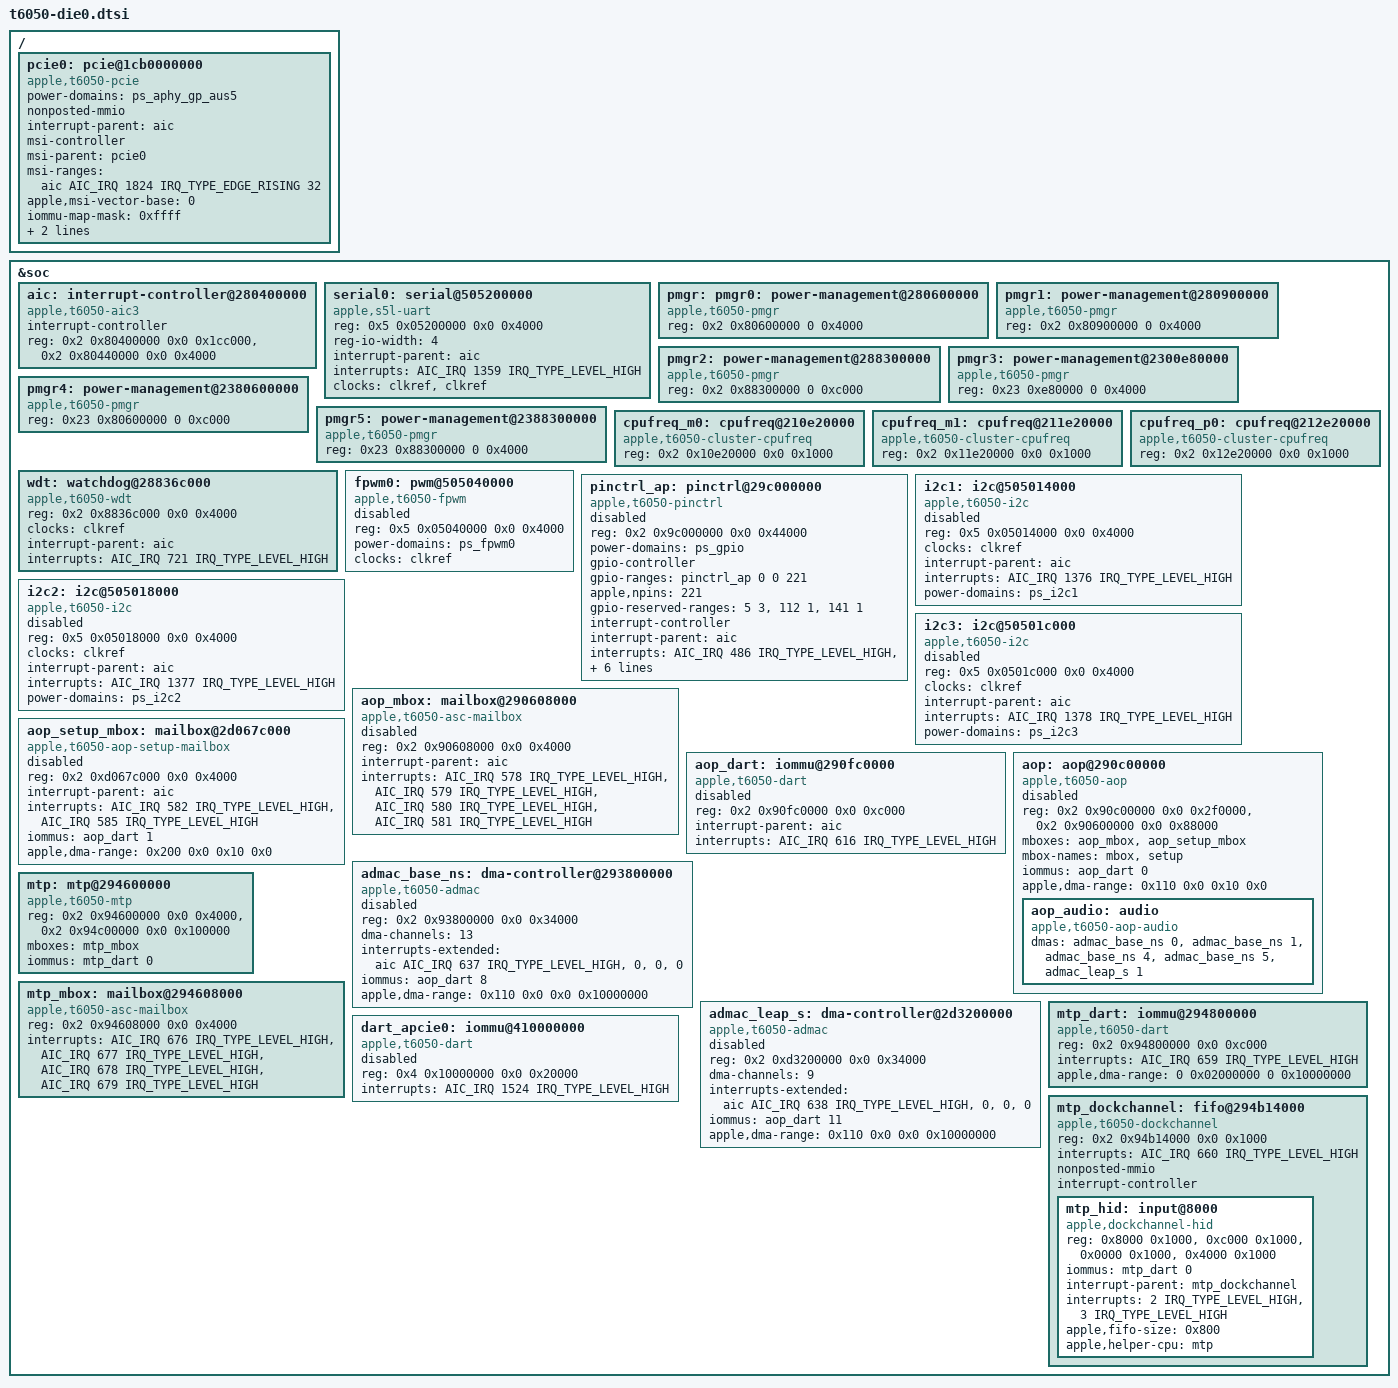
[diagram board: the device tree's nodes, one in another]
// SPDX-License-Identifier: GPL-2.0+ OR MIT
/*
 * Devices on the Apple T6050 "M5 Max" SoC (single die)
 *
 * Register windows from the live J714c device tree (dumps/j714c.adt).
 * The six pmgr register blocks are declared here; their power domains
 * live in t6050-pmgr.dtsi.
 *
 * Copyright The Asahi Linux Contributors
 */

&soc {
	aic: interrupt-controller@280400000 {
		compatible = "apple,t6050-aic3", "apple,t8142-aic3", "apple,t8122-aic3";
		#interrupt-cells = <3>;
		interrupt-controller;

		reg = <0x2 0x80400000 0x0 0x1cc000>,
		      <0x2 0x80440000 0x0 0x4000>;
		reg-names = "core", "event";
	};

	serial0: serial@505200000 {
		compatible = "apple,s5l-uart";
		reg = <0x5 0x05200000 0x0 0x4000>;
		reg-io-width = <4>;
		interrupt-parent = <&aic>;
		interrupts = <AIC_IRQ 1359 IRQ_TYPE_LEVEL_HIGH>;
		clocks = <&clkref>, <&clkref>;
		clock-names = "uart", "clk_uart_baud0";
	};

	pmgr: pmgr0: power-management@280600000 {
		compatible = "apple,t6050-pmgr", "apple,t8103-pmgr", "syscon", "simple-mfd";
		reg = <0x2 0x80600000 0 0x4000>;
		#address-cells = <1>;
		#size-cells = <1>;
	};

	pmgr1: power-management@280900000 {
		compatible = "apple,t6050-pmgr", "apple,t8103-pmgr", "syscon", "simple-mfd";
		reg = <0x2 0x80900000 0 0x4000>;
		#address-cells = <1>;
		#size-cells = <1>;
	};

	pmgr2: power-management@288300000 {
		compatible = "apple,t6050-pmgr", "apple,t8103-pmgr", "syscon", "simple-mfd";
		reg = <0x2 0x88300000 0 0xc000>;
		#address-cells = <1>;
		#size-cells = <1>;
	};

	pmgr3: power-management@2300e80000 {
		compatible = "apple,t6050-pmgr", "apple,t8103-pmgr", "syscon", "simple-mfd";
		reg = <0x23 0xe80000 0 0x4000>;
		#address-cells = <1>;
		#size-cells = <1>;
	};

	pmgr4: power-management@2380600000 {
		compatible = "apple,t6050-pmgr", "apple,t8103-pmgr", "syscon", "simple-mfd";
		reg = <0x23 0x80600000 0 0xc000>;
		#address-cells = <1>;
		#size-cells = <1>;
	};

	pmgr5: power-management@2388300000 {
		compatible = "apple,t6050-pmgr", "apple,t8103-pmgr", "syscon", "simple-mfd";
		reg = <0x23 0x88300000 0 0x4000>;
		#address-cells = <1>;
		#size-cells = <1>;
	};

	cpufreq_m0: cpufreq@210e20000 {
		compatible = "apple,t6050-cluster-cpufreq", "apple,cluster-cpufreq";
		reg = <0x2 0x10e20000 0x0 0x1000>;
		#performance-domain-cells = <0>;
	};

	cpufreq_m1: cpufreq@211e20000 {
		compatible = "apple,t6050-cluster-cpufreq", "apple,cluster-cpufreq";
		reg = <0x2 0x11e20000 0x0 0x1000>;
		#performance-domain-cells = <0>;
	};

	cpufreq_p0: cpufreq@212e20000 {
		compatible = "apple,t6050-cluster-cpufreq", "apple,cluster-cpufreq";
		reg = <0x2 0x12e20000 0x0 0x1000>;
		#performance-domain-cells = <0>;
	};

	wdt: watchdog@28836c000 {
		compatible = "apple,t6050-wdt", "apple,t8103-wdt";
		reg = <0x2 0x8836c000 0x0 0x4000>;
		clocks = <&clkref>;
		interrupt-parent = <&aic>;
		interrupts = <AIC_IRQ 721 IRQ_TYPE_LEVEL_HIGH>;
	};

	fpwm0: pwm@505040000 {
		compatible = "apple,t6050-fpwm", "apple,s5l-fpwm";
		reg = <0x5 0x05040000 0x0 0x4000>;
		power-domains = <&ps_fpwm0>;
		clocks = <&clkref>;
		#pwm-cells = <2>;
		status = "disabled";
	};

	/*
	 * AP GPIO block. ADT /arm-io/gpio0: 0x9c000000 + 0x44000, 221 pins,
	 * seven AIC interrupts, no-restore-gpio-pins 5 6 7 112 141. The t8140
	 * driver variant: slots in the block fault when read, so the regmap is
	 * not cache-initialised and stays inside the valid pins minus the
	 * reserved ranges (the firmware's no-restore pins, as t8140.dtsi).
	 * Enabled by the board DT together with its first users, the audio
	 * codec reset, shutdown and interrupt lines.
	 */
	pinctrl_ap: pinctrl@29c000000 {
		compatible = "apple,t6050-pinctrl", "apple,t8140-pinctrl";
		reg = <0x2 0x9c000000 0x0 0x44000>;
		power-domains = <&ps_gpio>;

		gpio-controller;
		#gpio-cells = <2>;
		gpio-ranges = <&pinctrl_ap 0 0 221>;
		apple,npins = <221>;
		gpio-reserved-ranges = <5 3>, <112 1>, <141 1>;

		interrupt-controller;
		#interrupt-cells = <2>;
		interrupt-parent = <&aic>;
		interrupts = <AIC_IRQ 486 IRQ_TYPE_LEVEL_HIGH>,
			     <AIC_IRQ 487 IRQ_TYPE_LEVEL_HIGH>,
			     <AIC_IRQ 488 IRQ_TYPE_LEVEL_HIGH>,
			     <AIC_IRQ 489 IRQ_TYPE_LEVEL_HIGH>,
			     <AIC_IRQ 490 IRQ_TYPE_LEVEL_HIGH>,
			     <AIC_IRQ 491 IRQ_TYPE_LEVEL_HIGH>,
			     <AIC_IRQ 492 IRQ_TYPE_LEVEL_HIGH>;
		status = "disabled";
	};

	/*
	 * I2C controllers. ADT /arm-io/i2c1..3: 0x305014000, 0x305018000,
	 * 0x30501c000 (+ 0x4000 each), AIC interrupts 1376-1378, pmgr I2C1-3.
	 * SCL/SDA are AP pins 60/61, 62/63 and 64/65; iBoot leaves them muxed
	 * (it drives the speaker amps for the boot chime), so no pin groups are
	 * set here. i2c1 and i2c3 carry the speaker amps, i2c2 the jack codec.
	 */
	i2c1: i2c@505014000 {
		compatible = "apple,t6050-i2c", "apple,t8103-i2c";
		reg = <0x5 0x05014000 0x0 0x4000>;
		clocks = <&clkref>;
		interrupt-parent = <&aic>;
		interrupts = <AIC_IRQ 1376 IRQ_TYPE_LEVEL_HIGH>;
		#address-cells = <1>;
		#size-cells = <0>;
		power-domains = <&ps_i2c1>;
		status = "disabled";
	};

	i2c2: i2c@505018000 {
		compatible = "apple,t6050-i2c", "apple,t8103-i2c";
		reg = <0x5 0x05018000 0x0 0x4000>;
		clocks = <&clkref>;
		interrupt-parent = <&aic>;
		interrupts = <AIC_IRQ 1377 IRQ_TYPE_LEVEL_HIGH>;
		#address-cells = <1>;
		#size-cells = <0>;
		power-domains = <&ps_i2c2>;
		status = "disabled";
	};

	i2c3: i2c@50501c000 {
		compatible = "apple,t6050-i2c", "apple,t8103-i2c";
		reg = <0x5 0x0501c000 0x0 0x4000>;
		clocks = <&clkref>;
		interrupt-parent = <&aic>;
		interrupts = <AIC_IRQ 1378 IRQ_TYPE_LEVEL_HIGH>;
		#address-cells = <1>;
		#size-cells = <0>;
		power-domains = <&ps_i2c3>;
		status = "disabled";
	};

	/*
	 * AOP (always-on processor) and the audio DMA it owns. ADT /arm-io/aop
	 * (iop,ascwrap-v6, pre-loaded firmware mac17jaop): asc 0x90600000+0x88000,
	 * mmio 0x90c00000+0x2f0000, mailbox AIC 578-581 (ADT order [579 578 581
	 * 580] = send-not-empty, send-empty, recv-not-empty, recv-empty, as mtp);
	 * no AP power or clock gates. /arm-io/aop-exclave-mailbox
	 * (iop,secure-rtbuddy-proxy, T8140's "setup port"): 0x2d067c000+0x4000,
	 * ADT interrupts [585 582], dart-aop mapper 1; reading it hangs the AP,
	 * and the firmware boots without it, so it is not described. /arm-io/dart-aop:
	 * 0x90fc0000+0xc000, AIC 616, mappers aop 0, exclave-aop 1,
	 * admac-base-ns 8, admac-leap-ns 10, admac-leap-s 11.
	 * /arm-io/admac-base-ns (admac-evolution,t6050): 0x93800000+0x34000,
	 * AIC 637, 13 tx + 13 rx channels. DMA windows as t8140.dtsi: the ADT
	 * has the same vm-base-0 (0x10040000000) and vm-base-1 (0x20000000000).
	 */
	aop_mbox: mailbox@290608000 {
		compatible = "apple,t6050-asc-mailbox", "apple,asc-mailbox-v4";
		reg = <0x2 0x90608000 0x0 0x4000>;
		interrupt-parent = <&aic>;
		interrupts = <AIC_IRQ 578 IRQ_TYPE_LEVEL_HIGH>,
			     <AIC_IRQ 579 IRQ_TYPE_LEVEL_HIGH>,
			     <AIC_IRQ 580 IRQ_TYPE_LEVEL_HIGH>,
			     <AIC_IRQ 581 IRQ_TYPE_LEVEL_HIGH>;
		interrupt-names = "send-empty", "send-not-empty",
				  "recv-empty", "recv-not-empty";
		#mbox-cells = <0>;
		status = "disabled";
	};

	/*
	 * The AOP's "setup port": ADT /arm-io/aop-exclave-mailbox
	 * (iop,secure-rtbuddy-proxy), the ASC's second mailbox 1 GiB above
	 * it as on T8140, interrupts [585, 582], messages through dart-aop
	 * stream 1 (mapper-exclave-aop, vm-base-1 0x20000000000). The
	 * firmware's TRUSTED compartment serves three endpoints on it (0x20,
	 * 0x23, 0x32) and may only use DRAM in that stream-1 window; its AFK
	 * endpoints on the main mailbox answer only after this handshake.
	 */
	aop_setup_mbox: mailbox@2d067c000 {
		compatible = "apple,t6050-aop-setup-mailbox", "apple,t8140-aop-setup-mailbox";
		reg = <0x2 0xd067c000 0x0 0x4000>;
		interrupt-parent = <&aic>;
		interrupts = <AIC_IRQ 582 IRQ_TYPE_LEVEL_HIGH>,
			     <AIC_IRQ 585 IRQ_TYPE_LEVEL_HIGH>;
		interrupt-names = "send-empty", "recv-not-empty";
		iommus = <&aop_dart 1>;
		apple,dma-range = <0x200 0x0 0x10 0x0>;
		#mbox-cells = <0>;
		status = "disabled";
	};

	aop_dart: iommu@290fc0000 {
		/*
		 * Locked by the loader with inherited roots, like mtp_dart: the
		 * t8142 compatible turns on apple-dart's retained-root path
		 * (fw_mirror), which the plain t8110 fallback leaves off.
		 */
		compatible = "apple,t6050-dart", "apple,t8142-dart", "apple,t8110-dart";
		reg = <0x2 0x90fc0000 0x0 0xc000>;
		#iommu-cells = <1>;
		interrupt-parent = <&aic>;
		interrupts = <AIC_IRQ 616 IRQ_TYPE_LEVEL_HIGH>;
		status = "disabled";
	};

	aop: aop@290c00000 {
		compatible = "apple,t6050-aop";
		reg = <0x2 0x90c00000 0x0 0x2f0000>,
		      <0x2 0x90600000 0x0 0x88000>;
		reg-names = "mmio", "asc";
		mboxes = <&aop_mbox>, <&aop_setup_mbox>;
		mbox-names = "mbox", "setup";
		iommus = <&aop_dart 0>;
		/*
		 * The firmware's UNTRUSTED compartment (the AFK side) may only
		 * use DRAM at IOVA 0x10040078000..0x20000000000 (its cL4 mmio
		 * list); a host buffer elsewhere makes it panic. Stream 0's
		 * inherited root holds the firmware's own slot 16; the host's
		 * buffers go into the next slot, as on T8140.
		 */
		apple,dma-range = <0x110 0x0 0x10 0x0>;
		status = "disabled";

		/*
		 * The AOPAudioService streams on the base-ns ADMAC (ADT
		 * /arm-io/iop-audio-controller): audio-speaker tx-0 and rx-0
		 * (6 x 32-bit out, 12 x 16-bit V/I sense back), audio-codec-
		 * output tx-2, audio-codec-input rx-2. The ADT's tx-N is Linux
		 * channel 2N and rx-N is 2N+1 (apple-admac hardwires even
		 * channels to MEM_TO_DEV). No power domains: the audio fabric
		 * is the firmware's.
		 */
		aop_audio: audio {
			compatible = "apple,t6050-aop-audio";
			dmas = <&admac_base_ns 0>, <&admac_base_ns 1>,
			       <&admac_base_ns 4>, <&admac_base_ns 5>,
			       <&admac_leap_s 1>;
			/*
			 * "hpai" is the microphone array: the ADT routes
			 * audio-hp-mic to leap-s-adma-rx-0, Linux channel 1 of
			 * the LEAP-S ADMAC (even channels transmit, odd receive).
			 */
			dma-names = "spkr", "spkr-sense", "cout", "cin", "hpai";
			#sound-dai-cells = <1>;
		};
	};

	admac_base_ns: dma-controller@293800000 {
		compatible = "apple,t6050-admac", "apple,t8140-admac";
		reg = <0x2 0x93800000 0x0 0x34000>;
		dma-channels = <13>;
		interrupts-extended = <&aic AIC_IRQ 637 IRQ_TYPE_LEVEL_HIGH>,
				      <0>, <0>, <0>;
		#dma-cells = <1>;
		iommus = <&aop_dart 8>;
		apple,dma-range = <0x110 0x0 0x0 0x10000000>;
		status = "disabled";
	};

	/*
	 * The LEAP-S ADMAC through its non-secure proxy aperture: ADT
	 * /arm-io/admac-hp-mic-ec-proxy at 0x2d3200000 = admac-leap-s
	 * 0x293200000 + 1 GiB, the T8140 pattern (its admac_leap_s sits at
	 * 0x353200000 = 0x313200000 + 1 GiB). dart-aop stream 11. The AOP
	 * firmware owns the LEAP fabric: no resets and no AP power domains;
	 * the hpai service's pw0 raises it before a channel is requested.
	 */
	admac_leap_s: dma-controller@2d3200000 {
		compatible = "apple,t6050-admac", "apple,t8140-admac";
		reg = <0x2 0xd3200000 0x0 0x34000>;
		dma-channels = <9>;
		interrupts-extended = <&aic AIC_IRQ 638 IRQ_TYPE_LEVEL_HIGH>,
				      <0>, <0>, <0>;
		#dma-cells = <1>;
		iommus = <&aop_dart 11>;
		apple,dma-range = <0x110 0x0 0x0 0x10000000>;
		status = "disabled";
	};

	/*
	 * J714c also has a dockchannel UART (aapl,dock-channels,
	 * 0x88e28000/0x10004 + 0x88e0c000/0x18, AIC IRQ 360). The in-tree
	 * apple,dockchannel-uart driver expects three named windows
	 * (data/config/irq) and its observability from this laptop without
	 * a debug cable is unverified, so it is left out of the first boot.
	 * Add it with the window layout resolved when it is needed.
	 */

	/*
	 * MTP coprocessor and dockchannel HID (keyboard, trackpad), on the
	 * t8142 J813 layout. Addresses from the J714c ADT: mtp 0x294600000,
	 * dart-mtp 0x294800000 (0xc000), dockchannel-mtp 0x294b14000 (irq) and
	 * 0x294b28000.. (data windows). The ADT lists no power or clock gates.
	 */
	mtp: mtp@294600000 {
		compatible = "apple,t6050-mtp", "apple,t8142-rtk-helper-asc4",
			     "apple,mtp", "apple,rtk-helper-asc4";
		/* The second region is firmware SRAM, not the ASC control window. */
		reg = <0x2 0x94600000 0x0 0x4000>, <0x2 0x94c00000 0x0 0x100000>;
		reg-names = "asc", "sram";
		mboxes = <&mtp_mbox>;
		iommus = <&mtp_dart 0>;
	};

	mtp_mbox: mailbox@294608000 {
		compatible = "apple,t6050-asc-mailbox", "apple,asc-mailbox-v4";
		reg = <0x2 0x94608000 0x0 0x4000>;
		interrupts = <AIC_IRQ 676 IRQ_TYPE_LEVEL_HIGH>,
			     <AIC_IRQ 677 IRQ_TYPE_LEVEL_HIGH>,
			     <AIC_IRQ 678 IRQ_TYPE_LEVEL_HIGH>,
			     <AIC_IRQ 679 IRQ_TYPE_LEVEL_HIGH>;
		interrupt-names = "send-empty", "send-not-empty", "recv-empty", "recv-not-empty";
		#mbox-cells = <0>;
	};

	mtp_dart: iommu@294800000 {
		compatible = "apple,t6050-dart", "apple,t8142-dart", "apple,t8110-dart";
		reg = <0x2 0x94800000 0x0 0xc000>;
		interrupts = <AIC_IRQ 659 IRQ_TYPE_LEVEL_HIGH>;
		#iommu-cells = <1>;
		/* Keep host allocations clear of firmware's low IOVA mappings. */
		apple,dma-range = <0 0x02000000 0 0x10000000>;
	};

	/*
	 * /arm-io/dart-apcie0: apcie port 0's, which carries the N1 (its mappers Control, Alpha and
	 * Beta on streams 1, 2 and 3). The port is trained before Linux (pcie-exp1-host.py v13 over
	 * the proxy, later the resident m1n1); the board file enables it.
	 */
	dart_apcie0: iommu@410000000 {
		compatible = "apple,t6050-dart", "apple,t8110-dart";
		reg = <0x4 0x10000000 0x0 0x20000>;
		interrupts = <AIC_IRQ 1524 IRQ_TYPE_LEVEL_HIGH>;
		#iommu-cells = <1>;
		status = "disabled";
	};

	mtp_dockchannel: fifo@294b14000 {
		compatible = "apple,t6050-dockchannel", "apple,dockchannel";
		reg = <0x2 0x94b14000 0x0 0x1000>;
		reg-names = "irq";
		interrupts = <AIC_IRQ 660 IRQ_TYPE_LEVEL_HIGH>;
		ranges = <0 0x2 0x94b28000 0x20000>;
		nonposted-mmio;
		#address-cells = <1>;
		#size-cells = <1>;
		interrupt-controller;
		#interrupt-cells = <2>;

		mtp_hid: input@8000 {
			compatible = "apple,dockchannel-hid";
			reg = <0x8000 0x1000>, <0xc000 0x1000>,
			      <0x0000 0x1000>, <0x4000 0x1000>;
			reg-names = "config", "data", "rmt-config", "rmt-data";
			iommus = <&mtp_dart 0>;
			interrupt-parent = <&mtp_dockchannel>;
			interrupts = <2 IRQ_TYPE_LEVEL_HIGH>, <3 IRQ_TYPE_LEVEL_HIGH>;
			interrupt-names = "tx", "rx";
			apple,fifo-size = <0x800>;
			apple,helper-cpu = <&mtp>;
		};
	};
};

/ {
	/*
	 * The internal PCIe host (apcie), as aurora-silicon's t6050-die0.dtsi (j716c/dt) has it: the
	 * boot stage trains the links of the ports the board uses and keeps power, clocks, the PHYs
	 * and PERST; Linux owns the routing, MSI and the DARTs. The board names its ports (registers,
	 * interrupts, iommu-map, bus-range, a node per port). One MSI domain for all ports; the
	 * J714c's ADT gives pci-bridge0 vectors 0-31 of apcie0's 128 (AIC 1824 + vector).
	 */
	pcie0: pcie@1cb0000000 {
		compatible = "apple,t6050-pcie";
		device_type = "pci";
		/* The GP port's domain; its parents up to ps_apcie_gp follow it. */
		power-domains = <&ps_aphy_gp_aus5>;
		nonposted-mmio;
		interrupt-parent = <&aic>;

		msi-controller;
		msi-parent = <&pcie0>;
		msi-ranges = <&aic AIC_IRQ 1824 IRQ_TYPE_EDGE_RISING 32>;
		apple,msi-vector-base = <0>;

		iommu-map-mask = <0xffff>;
		dma-coherent;
		linux,pci-domain = <0>;
		#address-cells = <3>;
		#size-cells = <2>;
		ranges = <0x02000000 0x0 0x80000000 0xb 0x80000000 0x0 0x40000000>,
			 <0x43000000 0xb 0xc0000000 0xb 0xc0000000 0x0 0x20000000>;
	};
};
